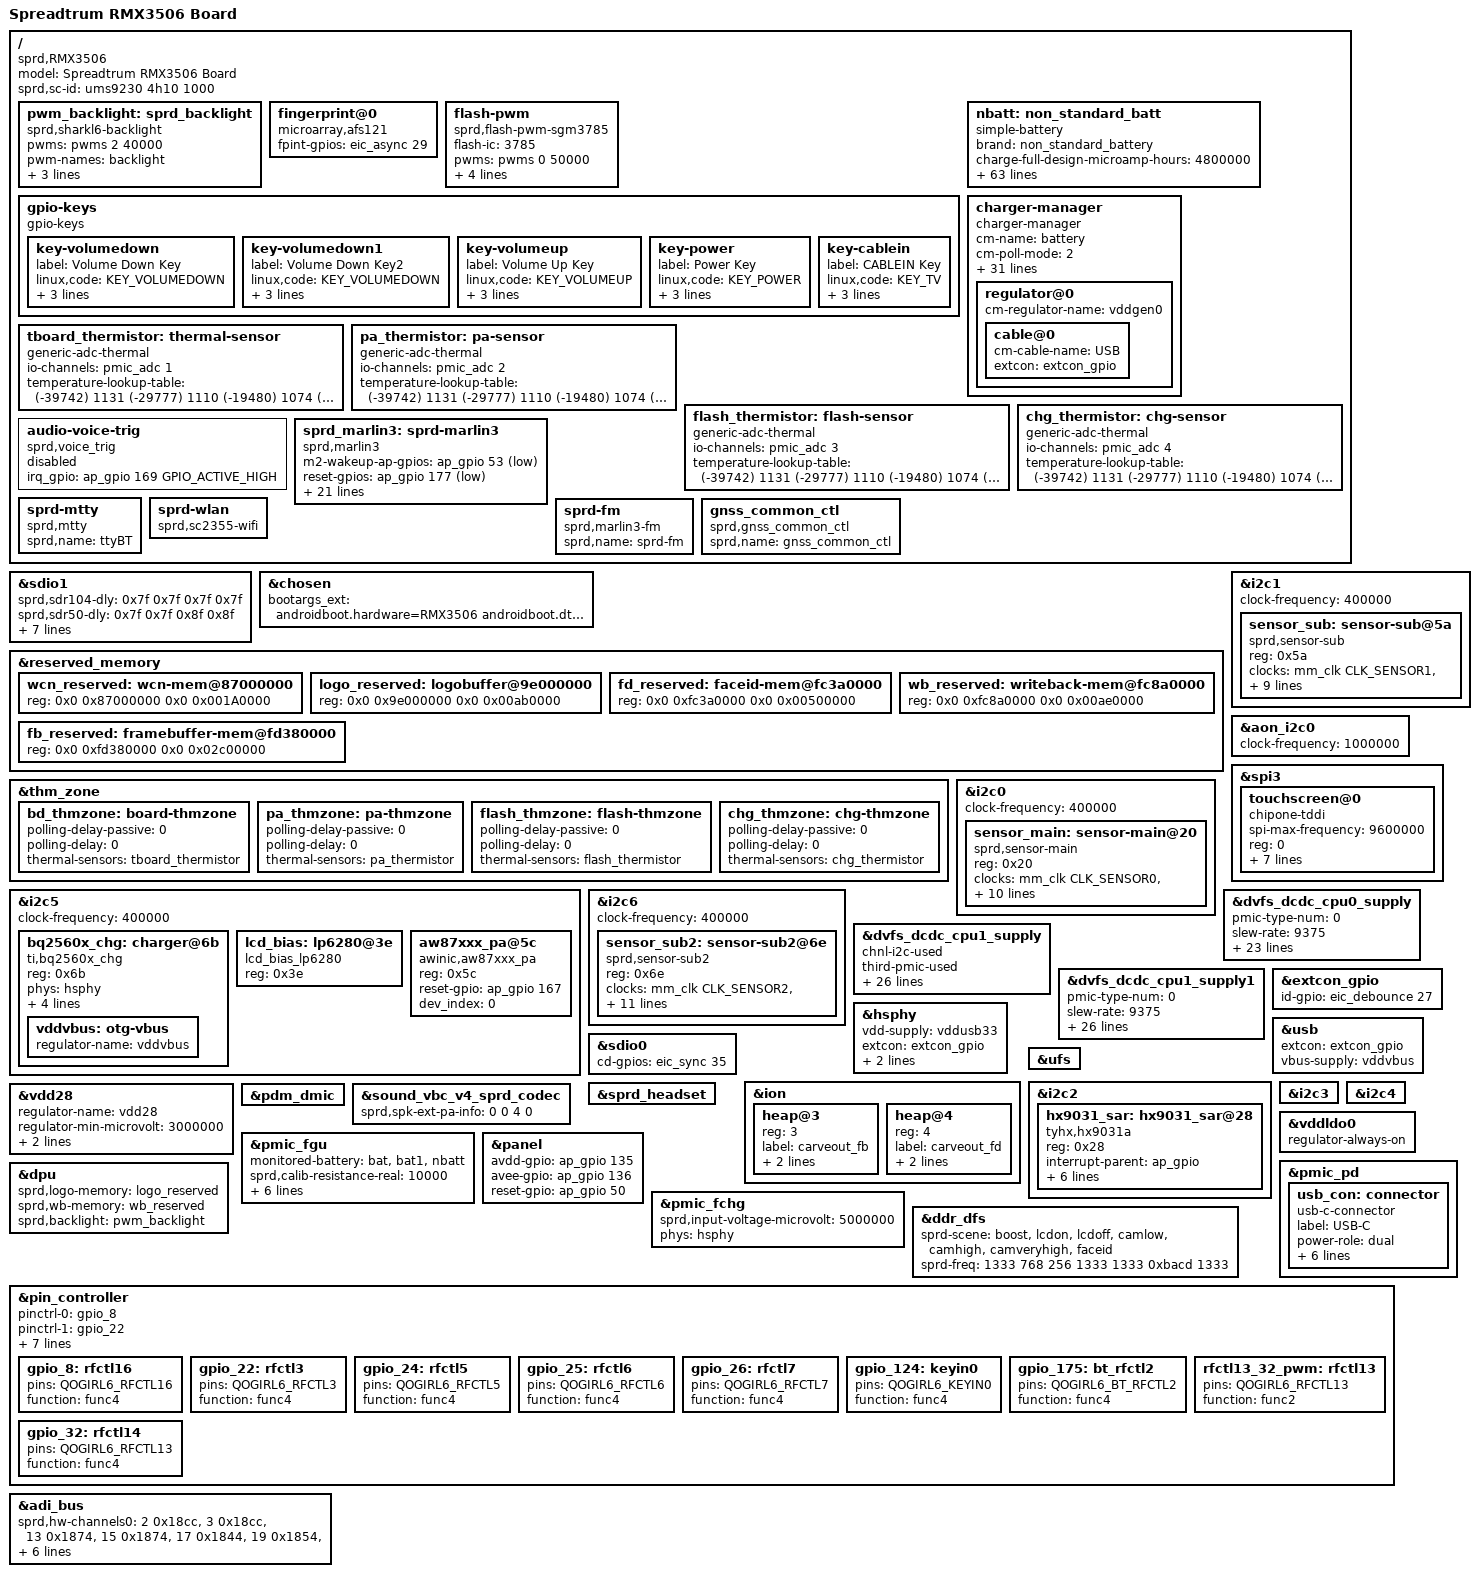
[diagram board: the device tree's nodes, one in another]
/dts-v1/;
/plugin/;
#include <dt-bindings/input/input.h>
#include <dt-bindings/gpio/gpio.h>
#include <dt-bindings/clock/sprd,ums9230-clk.h>
#include <dt-bindings/mfd/sprd,sc2730-regs.h>
#include <dt-bindings/mfd/sprd,sc2730-mask.h>
#include <dt-bindings/pinctrl/pinctrl-sprd.h>
#include <dt-bindings/usb/pd.h>
#include "lcd/lcd_icnl9911c_hkc_mipi_hd.dtsi"
#include "lcd/lcd_ili9882q_txd_mipi_hd.dtsi"
#include "lcd/lcd_icnl9911c_auo_mipi_hd.dtsi"
#include "lcd/lcd_dummy_mipi.dtsi"
#include "battery/RMX3506_REALME_LWN_4V45_5000mah.dtsi"
#include "battery/RMX3506_REALME_ATL_4V45_5000mah.dtsi"

/ {

	model = "Spreadtrum RMX3506 Board";

	compatible = "sprd,RMX3506";

	sprd,sc-id = "ums9230 4h10 1000";
	fragment {
		target-path = "/";
		__overlay__ {
			pwm_backlight: sprd_backlight {
				compatible = "sprd,sharkl6-backlight";
				pwms = <&pwms 2 40000>;
				pwm-names = "backlight";
				sprd,max-brightness-level = <3696>;
				default-brightness-level = <1048>;
				sprd,brightness-scale = <4095>;
			};

			fingerprint@0 {
				compatible = "microarray,afs121";
				fpint-gpios = <&eic_async 29 0>;
			};

			flash-pwm {
				compatible = "sprd,flash-pwm-sgm3785";
				flash-ic = <3785>;
				pwms = <&pwms 0 50000>;
				flash-en-gpios = <&ap_gpio 139 0>;
				flash-enm-gpios = <&ap_gpio 32 0>;
				pinctrl-names = "rfctl13_32_pwm","gpio_32";
				pinctrl-0 = <&rfctl13_32_pwm>;
				pinctrl-1 = <&gpio_32>;
				status = "okay";
			};

			gpio-keys {
				compatible = "gpio-keys";

				key-volumedown {
					label = "Volume Down Key";
					linux,code = <KEY_VOLUMEDOWN>;
					gpios = <&ap_gpio 124 GPIO_ACTIVE_LOW>;
					debounce-interval = <2>;
					wakeup-source;
				};
				
				key-volumedown1 {
					label = "Volume Down Key2";
					linux,code = <KEY_VOLUMEDOWN>;
					gpios = <&ap_gpio 126 GPIO_ACTIVE_LOW>;
					debounce-interval = <2>;
 					wakeup-source;
 				};

				key-volumeup {
					label = "Volume Up Key";
					linux,code = <KEY_VOLUMEUP>;
					gpios = <&pmic_eic 4 GPIO_ACTIVE_HIGH>;
					debounce-interval = <2>;
					wakeup-source;
				};

				key-power {
					label = "Power Key";
					linux,code = <KEY_POWER>;
					gpios = <&pmic_eic 1 GPIO_ACTIVE_LOW>;
					debounce-interval = <2>;
					wakeup-source;
				};
				key-cablein {
					label = "CABLEIN Key";
					linux,code = <KEY_TV>;
					gpios = <&ap_gpio 164 GPIO_ACTIVE_HIGH>;
					debounce-interval = <2>;
					wakeup-source;
				};
			};

			nbatt: non_standard_batt {
				compatible = "simple-battery";
				brand = "non_standard_battery";
				charge-full-design-microamp-hours = <4800000>;
				charge-term-current-microamp = <240000>;
				constant_charge_voltage_max_microvolt = <4432000>;
				factory-internal-resistance-micro-ohms = <130000>;
				voltage-min-design-microvolt = <3450000>;
				ocv-capacity-celsius = <20>;
				ocv-capacity-table-0 = <4380000 100>, <4317000 95>, <4258000 90>,
							<4200000 85>, <4145000 80>, <4092000 75>,
							<4047000 70>, <3990000 65>, <3955000 60>,
							<3900000 55>, <3861000 50>, <3834000 45>,
							<3813000 40>, <3796000 35>, <3783000 30>,
							<3770000 25>, <3752000 20>, <3730000 15>,
							<3698000 10>, <3687000 5>, <3400000 0>;
				 voltage-temp-table = <1404000 650>, <1307000 700>, <1203000 750>,
							<1095000 800>, <986000 850>, <878000 900>,
							<775000 950>, <678000 1000>, <590000 1050>,
							<510000 1100>, <440000 1150>, <378000 1200>,
							<324000 1250>, <278000 1300>, <238000 1350>,
							<204000 1400>, <175000 1450>, <150000 1500>,
							<129000 1550>, <111000 1600>, <96000 1650>,
							<83000 1700>, <73000 1750>, <63000 1800>,
							<55000 1850>, <48000 1900>, <42000 1950>;
				capacity-temp-table = <45 100>, <25 100>, <10 98>, <0 93>, <(-10) 85>, <(-20) 64>;
				resistance-temp-table = <45 100>, <25 100>, <10 546>, <0 769>, <(-10) 892>, <(-20) 923>;
				charge-sdp-current-microamp = <500000 600000>;
				charge-dcp-current-microamp = <2000000 3250000>;
				charge-cdp-current-microamp = <1500000 3250000>;
				charge-unknown-current-microamp = <1200000 1200000>;
		                cm-dcp-jeita-temp-table = <900 901 0 4435000 0 4435000>,
							<1000 1030 1000000 4435000 750000 4180000>,
							<1050 1080 2250000 4435000 1250000 4435000>,
							<1120 1150 2250000 4435000 2250000 4435000>,
							<1160 1190 3250000 4435000 2250000 4180000>,
							<1450 1420 3250000 4435000 3250000 4435000>,
							<1530 1500 1250000 4130000 1250000 4130000>;
				cm-sdp-jeita-temp-table = <900 901 0 4435000 0 4435000>,
							<1000 1030 600000 4435000 600000 4180000>,
							<1050 1080 600000 4435000 600000 4435000>,
							<1120 1150 600000 4435000 600000 4435000>,
							<1160 1190 600000 4435000 600000 4180000>,
							<1450 1420 600000 4435000 600000 4435000>,
							<1530 1500 600000 4130000 600000 4130000>;
				cm-cdp-jeita-temp-table = <900 901 0 4435000 0 4435000>,
							<1000 1030 1000000 4435000 750000 4180000>,
							<1050 1080 2250000 4435000 1250000 4180000>,
							<1120 1150 2250000 4435000 2250000 4435000>,
							<1160 1190 3250000 4435000 2250000 4180000>,
							<1450 1420 3250000 4435000 3250000 4435000>,
							<1530 1500 1250000 4130000 1250000 4130000>;
				cm-unknown-jeita-temp-table = <900 901 0 4435000 0 4180000>,
							<1000 1030 480000 4435000 480000 4180000>,
							<1050 1080 480000 4435000 480000 4435000>,
							<1120 1150 1000000 4435000 1000000 4435000>,
							<1160 1190 1200000 4435000 1200000 4435000>,
							<1450 1420 1200000 4435000 1200000 4435000>,
							<1530 1500 1000000 4130000 1000000 4130000>;
			};


			charger-manager {
				compatible = "charger-manager";
				cm-name = "battery";
				cm-poll-mode = <2>;
				cm-poll-interval = <5000>;
				cm-battery-stat = <2>;

				cm-fullbatt-vchkdrop-ms = <30000>;
				cm-fullbatt-vchkdrop-volt = <60000>;
				cm-fullbatt-voltage = <4395000 4395000>;
				cm-fullbatt-current = <260000>;
				cm-fullbatt-capacity = <100>;

				cm-num-chargers = <1>;
				cm-num-fast-chargers = <1>;
				cm-chargers = "bq2560x_charger";
				cm-fuel-gauge = "sc27xx-fgu";
				cm-fast-chargers = "sc2730_fast_charger";

				/* in deci centigrade */
				cm-battery-cold = <200>;
				cm-battery-cold-in-minus;
				cm-battery-hot = <800>;
				cm-battery-temp-diff = <100>;

				/* Allow charging for 6hr */
				cm-charging-max = <72000000>;
				/* recovery charging after stop charging 45min */
				cm-discharging-max = <2700000>;

				/* the interval to feed charger watchdog */
				cm-wdt-interval = <60>;

				/* drop voltage in microVolts to allow shutdown */
				cm-shutdown-voltage = <3350000>;

				/* when 99% of the time is exceeded, it will be forced to 100% */
				cm-tickle-time-out = <1500>;

				/* how much time to allow capacity change */
				cm-one-cap-time = <30>;
				cm-thermal-zone = "board-thmzone";
				/* when the safe charging voltage is exceeded, stop charging */
				cm-charge-voltage-max = <5800000>;
				/* drop voltage in microVolts to restart charging */
				cm-charge-voltage-drop = <350000>;

				cm-force-jeita-status = <5>;

				cm-ir-cv-offset-microvolt = <100000>;
				cm-ir-rc = <20>;
				cm-ir-us-upper-limit-microvolt = <4500000>;

				monitored-battery = <&bat &bat1 &nbatt>;
				cm-capacity-track;

				//cm-cap-remap-table = <1 2 3>, <2 3 2>, <98 99 2>, <99 100 3>;

				regulator@0 {
					cm-regulator-name = "vddgen0";
					cable@0 {
						cm-cable-name = "USB";
						extcon = <&extcon_gpio>;
					};
				};
			};

			tboard_thermistor: thermal-sensor {
				compatible = "generic-adc-thermal";
				#thermal-sensor-cells = <0>;
				io-channels = <&pmic_adc 1>;
				io-channel-names = "sensor-channel";
				temperature-lookup-table = <
					(-39742) 1131
					(-29777) 1110
					(-19480) 1074
					(-4679) 983
					10110 838
					24805 654
					44922 413
					54903 316
					64895 238
					74884 178
					84883 133
					94883 100
					104880 75
					114889 57
					124872 43 >;
			};

			pa_thermistor: pa-sensor {
				compatible = "generic-adc-thermal";
				#thermal-sensor-cells = <0>;
				io-channels = <&pmic_adc 2>;
				io-channel-names = "sensor-channel";
				temperature-lookup-table = <
					(-39742) 1131
					(-29777) 1110
					(-19480) 1074
					(-4679) 983
					10110 838
					24805 654
					44922 413
					54903 316
					64895 238
					74884 178
					84883 133
					94883 100
					104880 75
					114889 57
					124872 43 >;
			};
			
			flash_thermistor: flash-sensor {
				compatible = "generic-adc-thermal";
				#thermal-sensor-cells = <0>;
				io-channels = <&pmic_adc 3>;
				io-channel-names = "sensor-channel";
				temperature-lookup-table = <
					(-39742) 1131
					(-29777) 1110
					(-19480) 1074
					(-4679) 983
					10110 838
					24805 654
					44922 413
					54903 316
					64895 238
					74884 178
					84883 133
					94883 100
					104880 75
					114889 57
					124872 43 >;
			};

			chg_thermistor: chg-sensor {
				compatible = "generic-adc-thermal";
				#thermal-sensor-cells = <0>;
				io-channels = <&pmic_adc 4>;
				io-channel-names = "sensor-channel";
				temperature-lookup-table = <
					(-39742) 1131
					(-29777) 1110
					(-19480) 1074
					(-4679) 983
					10110 838
					24805 654
					44922 413
					54903 316
					64895 238
					74884 178
					84883 133
					94883 100
					104880 75
					114889 57
					124872 43 >;
			};

			audio-voice-trig {
				status = "disable";
				compatible = "sprd,voice_trig";
				irq_gpio = <&ap_gpio 169 GPIO_ACTIVE_HIGH>;
			};

			sprd_marlin3: sprd-marlin3 {
				compatible = "sprd,marlin3";
				m2-wakeup-ap-gpios = <&ap_gpio 53 GPIO_ACTIVE_LOW>;
				reset-gpios = <&ap_gpio 177 GPIO_ACTIVE_LOW>;
				enable-gpios = <&ap_gpio 116 GPIO_ACTIVE_LOW>;
				m2-to-ap-irq-gpios = <&ap_gpio 52 GPIO_ACTIVE_LOW>;
				avdd12-supply = <&vddwcn>;
				avdd33-supply = <&vddwifipa>;
				dcxo18-supply = <&vddsim2>;
                                xtal-26m-clk-type = "TSX";
				clock-names = "clk_32k","source","enable";
				clocks = <&aon_clk CLK_AUX2>,
					 <&ext_32k>,
					 <&aonapb_gate CLK_AUX2_EB>;

				reg = <0 0x87000000 0 0x00100000>,
					<0 0x87100000 0 0xA0000>;
				reg-names = "btwf_mem", "gnss_mem";

				sdhci-name = <&sdio1>;
				sprd,btwf-file-name = "/dev/block/by-name/wcnmodem";
				sprd,gnss-file-name = "/dev/block/by-name/gnssmodem";
				adma-tx;
				adma-rx;

				/*
				 * bound parameter:
				 * [0]:addr offset, [1]:mask, [2]:unboundval, [3]:boundval
				 */
				/*avdd12-parent-bound-chip = <REG_ANA_SLP_DCDC_PD_CTRL MASK_ANA_SLP_DCDCGEN1_PD_EN 0x0 MASK_ANA_SLP_DCDCGEN1_PD_EN>;*/
				avdd12-bound-wbreq = <REG_ANA_LDO_XTL_EN10 MASK_ANA_LDO_VDDWCN_EXT_XTL3_EN 0x0 MASK_ANA_LDO_VDDWCN_EXT_XTL3_EN>;
				avdd33-bound-wbreq = <REG_ANA_LDO_XTL_EN11 MASK_ANA_LDO_VDDWIFIPA_EXT_XTL3_EN 0x0 MASK_ANA_LDO_VDDWIFIPA_EXT_XTL3_EN>;
			};

			sprd-mtty {
				compatible = "sprd,mtty";
				sprd,name = "ttyBT";
			};

			sprd-fm {
				compatible = "sprd,marlin3-fm";
				sprd,name = "sprd-fm";
			};

			gnss_common_ctl {
				compatible = "sprd,gnss_common_ctl";
				sprd,name = "gnss_common_ctl";
			};

			sprd-wlan{
				compatible = "sprd,sc2355-wifi";
			};
		};
	};
};

&sdio1 {
	sprd,sdr104-dly = <0x7f 0x7f 0x7f 0x7f>;
	sprd,sdr50-dly = <0x7f 0x7f 0x8f 0x8f>;
	sd-uhs-sdr104;
	sd-uhs-sdr50;
	bus-width = <4>;
	sprd,name = "sdio_wifi";
	sprd,sdio-adma;
	no-sd;
	no-mmc;
	status = "okay";
};

&chosen {
	bootargs_ext = "androidboot.hardware=RMX3506 androidboot.dtbo_idx=0";
};

&reserved_memory {
	wcn_reserved: wcn-mem@87000000 {
		reg = <0x0 0x87000000 0x0 0x001A0000>;
	};

	logo_reserved: logobuffer@9e000000{
		reg = <0x0 0x9e000000 0x0 0x00ab0000>;
	};

	fd_reserved: faceid-mem@fc3a0000 {
		reg = <0x0 0xfc3a0000 0x0 0x00500000>;
	};

	wb_reserved: writeback-mem@fc8a0000 {
		reg = <0x0 0xfc8a0000 0x0 0x00ae0000>;
	};

	fb_reserved: framebuffer-mem@fd380000 {
		reg = <0x0 0xfd380000 0x0 0x02c00000>;
	};
};

&thm_zone {
	bd_thmzone: board-thmzone {
		polling-delay-passive = <0>;
		polling-delay = <0>;
		thermal-sensors = <&tboard_thermistor>;
	};

	pa_thmzone: pa-thmzone {
		polling-delay-passive = <0>;
		polling-delay = <0>;
		thermal-sensors = <&pa_thermistor>;
	};
	
	flash_thmzone: flash-thmzone {
		polling-delay-passive = <0>;
		polling-delay = <0>;
		thermal-sensors = <&flash_thermistor>;
	};

	chg_thmzone: chg-thmzone {
		polling-delay-passive = <0>;
		polling-delay = <0>;
		thermal-sensors = <&chg_thermistor>;
	};
};

&i2c0 {
	status = "okay";
	clock-frequency = <400000>;

	sensor_main: sensor-main@20 {
		compatible = "sprd,sensor-main";
		reg = <0x20>;
		clock-names = "clk_src","sensor_eb",
			"clk_96m","clk_76m8",
			"clk_48m","clk_26m";
		clocks = <&mm_clk CLK_SENSOR0>,<&mm_gate CLK_MM_SENSOR0_EB>,
				<&pll1 CLK_TWPLL_96M>,<&pll1 CLK_TWPLL_76M8>,
				<&pll1 CLK_TWPLL_48M>,<&ext_26m>;
		vddio-supply = <&vddcamio>;
		vddcama-supply = <&vddcama0>;
		vddcamd-supply = <&vddcamd0>;
		vddcammot-supply = <&vddcammot>;
		reset-gpios = <&ap_gpio 45 0>;
		sprd,phyid = <0>;
		csi = <&csi0>;
	};
};

&i2c1 {
	status = "okay";
	clock-frequency = <400000>;

	sensor_sub: sensor-sub@5a {
		compatible = "sprd,sensor-sub";
		reg = <0x5a>;
		clock-names = "clk_src","sensor_eb",
			"clk_96m","clk_76m8",
			"clk_48m","clk_26m";
		clocks = <&mm_clk CLK_SENSOR1>,<&mm_gate CLK_MM_SENSOR1_EB>,
				<&pll1 CLK_TWPLL_96M>,<&pll1 CLK_TWPLL_76M8>,
				<&pll1 CLK_TWPLL_48M>,<&ext_26m>;
		vddio-supply = <&vddcamio>;
		vddcama-supply = <&vddcama1>;
		vddcamd-supply = <&vddcamd0>;
		reset-gpios = <&ap_gpio 44 0>;
		sprd,phyid = <2>;
		csi = <&csi0>;
	};
};

&i2c5 {
	status = "okay";
	clock-frequency = <400000>;

	bq2560x_chg: charger@6b {
		compatible = "ti,bq2560x_chg";
		reg = <0x6b>;
		phys = <&hsphy>;
		monitored-battery = <&bat &bat1 &nbatt>;
		extcon = <&extcon_gpio>;
		pd-extcon-enable;
		irq-gpio = <&ap_gpio 115 GPIO_ACTIVE_LOW>;
		vddvbus:otg-vbus {
			regulator-name = "vddvbus";
		};
	};

	lcd_bias: lp6280@3e{
		compatible = "lcd_bias_lp6280";
		reg = <0x3e>;
	};

	aw87xxx_pa@5c {
		compatible = "awinic,aw87xxx_pa";
		reg = <0x5c>;
		reset-gpio = <&ap_gpio 167 0>;
		dev_index = < 0 >;
		status = "okay";
	};
};

&i2c6 {
	status = "okay";
	clock-frequency = <400000>;

	sensor_sub2: sensor-sub2@6e {
		compatible = "sprd,sensor-sub2";
		reg = <0x6e>;
		clock-names = "clk_src","sensor_eb",
			"clk_96m","clk_76m8",
			"clk_48m","clk_26m";
		clocks = <&mm_clk CLK_SENSOR2>,<&mm_gate CLK_MM_SENSOR2_EB>,
			<&pll1 CLK_TWPLL_96M>,<&pll1 CLK_TWPLL_76M8>,
			<&pll1 CLK_TWPLL_48M>,<&ext_26m>;
		vddio-supply = <&vddcamio>;
		avdd-gpios = <&ap_gpio 130 0>;
		vddcamd-supply = <&vddcamd1>;
		vddcammot-supply = <&vddcammot>;
		mot-gpios = <&ap_gpio 112 0>;
		reset-gpios = <&ap_gpio 114 0>;
	/*	power-down-gpios = <&ap_gpio 40 0>;*/
		sprd,phyid = <3>;
		csi = <&csi2>;
	};
};

&aon_i2c0 {
	status = "okay";
	clock-frequency = <1000000>;
};

&spi3 {
	status = "okay";
	touchscreen@0 {
			compatible = "chipone-tddi","tchip,ilitek";
			spi-max-frequency = <9600000>;
			reg = <0>;
			/*chipone,irq-gpio = <&ap_gpio 144 GPIO_ACTIVE_HIGH>;*/
			chipone,irq-gpio = <&eic_async 16  GPIO_ACTIVE_HIGH>;
			chipone,rst-gpio = <&ap_gpio 145 GPIO_ACTIVE_HIGH>;
			chipone,panel-coords = <0 720 0 1600>;
			chipone,x-res = <720>;
			chipone,y-res = <1600>;
		//ili
		/*touch,irq-gpio = <&ap_gpio 144 GPIO_ACTIVE_HIGH>;*/
		touch,irq-gpio = <&eic_async 16 GPIO_ACTIVE_HIGH>;
		touch,reset-gpio = <&ap_gpio 145 GPIO_ACTIVE_HIGH>;		
	};
};

&dvfs_dcdc_cpu0_supply {
	pmic-type-num = <0>;
	slew-rate = <9375>; /* 9375uV/us */
	top-dvfs-adi-state = <0x70 0 0xf>;
	voltage-grade-num = <8>;
	voltage-grade = <0 0xf0 0xf4 0 0x1ff>,
		<1 0xf0 0xf4 9 0x1ff>,
		<2 0x100 0xf4 18 0x1ff>,
		<3 0x110 0xf8 0 0x1ff>,
		<4 0x120 0xf8 9 0x1ff>,
		<5 0x130 0xf8 18 0x1ff>,
		<6 0x140 0xfc 0 0x1ff>,
		<7 0x140 0xfc 9 0x1ff>;
	voltage-up-delay = <50 0x58 0 0xffff 0x600>,
		<100 0x58 16 0xffff 0xa00>,
		<150 0x54 0 0xffff 0xf00>,
		<200 0x54 16 0xffff 0x1400>,
		<250 0x50 0 0xffff 0x1900>,
		<300 0x50 16 0xffff 0x1e00>,
		<350 0x110 0 0xffff 0x2300>;
	voltage-down-delay = <50 0x64 0 0xffff 0x600>,
		<100 0x64 16 0xffff 0xa00>,
		<150 0x60 0 0xffff 0xf00>,
		<200 0x60 16 0xffff 0x1400>,
		<250 0x5c 0 0xffff 0x1900>,
		<300 0x5c 16 0xffff 0x1e00>,
		<350 0x114 0 0xffff 0x2300>;
	tuning-latency-us = <0>;
	chnl-in-i2c = <0>;
};

&dvfs_dcdc_cpu1_supply {
	chnl-i2c-used;
	third-pmic-used;
	pmic-type-num = <2>;
	slew-rate = <4000>; /* 4000uV/us */
	supply-type-sel = <0x120 0 1>;
	top-dvfs-i2c-state = <0x9c 4 0x1f>;
	voltage-grade-num = <8>;
	voltage-grade = <0 0x8f 0x12c 0 0xff>,
		<1 0x94 0x12c 8 0xff>,
		<2 0x99 0x12c 16 0xff>,
		<3 0x9e 0x12c 24 0xff>,
		<4 0xa3 0x130 0 0xff>,
		<5 0xa8 0x130 8 0xff>,
		<6 0xa8 0x130 16 0xff>,
		<7 0xa8 0x130 24 0xff>;
	voltage-up-delay = <50 0x84 0 0xffff 0x1600>,
		<100 0x84 16 0xffff 0x1a00>,
		<150 0x80 0 0xffff 0x1f00>,
		<200 0x80 16 0xffff 0x2400>,
		<250 0x7c 0 0xffff 0x2900>,
		<300 0x7c 16 0xffff 0x2e00>,
		<350 0x118 0 0xffff 0x3300>;
	voltage-down-delay = <50 0x90 0 0xffff 0x600>,
		<100 0x90 16 0xffff 0xa00>,
		<150 0x8c 0 0xffff 0xf00>,
		<200 0x8c 16 0xffff 0x1400>,
		<250 0x88 0 0xffff 0x1900>,
		<300 0x88 16 0xffff 0x1e00>,
		<350 0x11c 0 0xffff 0x2300>;
	tuning-latency-us = <0>;
	chnl-in-i2c = <1>;
};

&dvfs_dcdc_cpu1_supply1 {
	pmic-type-num = <0>;
	slew-rate = <9375>; /* 9375uV/us */
	supply-type-sel = <0x120 0 0>;
	top-dvfs-adi-state = <0x9c 0 0xf>;
	voltage-grade-num = <8>;
	voltage-grade = <0 0xf0 0x100 0 0x1ff>,
		<1 0x100 0x100 9 0x1ff>,
		<2 0x110 0x100 18 0x1ff>,
		<3 0x120 0x104 0 0x1ff>,
		<4 0x130 0x104 9 0x1ff>,
		<5 0x140 0x104 18 0x1ff>,
		<6 0x140 0x108 0 0x1ff>,
		<7 0x140 0x108 9 0x1ff>;
	voltage-up-delay = <50 0x84 0 0xffff 0x600>,
		<100 0x84 16 0xffff 0xa00>,
		<150 0x80 0 0xffff 0xf00>,
		<200 0x80 16 0xffff 0x1400>,
		<250 0x7c 0 0xffff 0x1900>,
		<300 0x7c 16 0xffff 0x1e00>,
		<350 0x118 0 0xffff 0x2300>;
	voltage-down-delay = <50 0x90 0 0xffff 0x600>,
		<100 0x90 16 0xffff 0xa00>,
		<150 0x8c 0 0xffff 0xf00>,
		<200 0x8c 16 0xffff 0x1400>,
		<250 0x88 0 0xffff 0x1900>,
		<300 0x88 16 0xffff 0x1e00>,
		<350 0x11c 0 0xffff 0x2300>;
	tuning-latency-us = <0>;
	chnl-in-i2c = <0>;
};
&extcon_gpio {
	id-gpio = <&eic_debounce 27 GPIO_ACTIVE_HIGH>;
};
&hsphy {
	vdd-supply = <&vddusb33>;
	extcon = <&extcon_gpio>;
	sprd,hsphy-device-eye-pattern = <0x04f3d1c0>;
	sprd,hsphy-host-eye-pattern = <0x04f3d1c0>;
	status = "okay";
};

&usb {
	extcon = <&extcon_gpio>;
	vbus-supply = <&vddvbus>;
	status = "okay";
};

&sdio0 {
	cd-gpios = <&eic_sync 35 GPIO_ACTIVE_HIGH>;
};

&ion {
	heap@3 {
		reg = <3>;
		label = "carveout_fb";
		type = <2>;
		memory-region = <&fb_reserved>;
	};
};

&ufs {
	status = "okay";
};

&i2c2 {
	status = "okay";
    hx9031_sar:hx9031_sar@28 {
		compatible = "tyhx,hx9031a";
		reg = <0x28>;
		interrupt-parent = <&ap_gpio>;
		interrupts = <176 0>;
		tyhx,nirq-gpio = <&ap_gpio 176 0x00>;
		grip-sensor = <0>;
		grip-sensor-sub = <1>;
		grip-sensor-wifi = <2>;
		tyhx,channel-flag = <0x07>;
	};
};

&i2c3 {
	status = "okay";
};

&i2c4 {
	status = "okay";
};

&vdd28 {
    regulator-name = "vdd28";
    regulator-min-microvolt = <3000000>;
    regulator-max-microvolt = <3000000>;
    regulator-always-on;
};

&sprd_headset {
	status = "okay";
};

&pdm_dmic {
	status = "okay";
};

&sound_vbc_v4_sprd_codec {
	status = "okay";
    sprd,spk-ext-pa-info = <0 0 4 0>;
 /*   sprd,spk-ext-pa-gpio = <&ap_gpio 167 0>;*/
};

&vddldo0 {
	regulator-always-on;
};

&pmic_fgu {
	monitored-battery = <&bat &bat1 &nbatt>;
	sprd,calib-resistance-real = <10000>;
	sprd,calib-resistance-spec = <20000>;
	first-calib-voltage = <3580000>;
	first-calib-capacity = <50>;
	sprd,comp-resistance-mohm = <8>;
	io-channels = <&pmic_adc 0>, <&pmic_adc 14>, <&pmic_adc 6>;
 	io-channel-names = "bat-temp", "charge-vol", "bat-id-vol";
};

&panel {
	avdd-gpio = <&ap_gpio 135 GPIO_ACTIVE_HIGH>;
	avee-gpio = <&ap_gpio 136 GPIO_ACTIVE_HIGH>;
	reset-gpio = <&ap_gpio 50 GPIO_ACTIVE_HIGH>;
};

&dpu {
	sprd,logo-memory = <&logo_reserved>;
	sprd,wb-memory = <&wb_reserved>;

	sprd,backlight = <&pwm_backlight>;
};

&pmic_fchg {
	sprd,input-voltage-microvolt = <5000000>;
	phys = <&hsphy>;
};

&pmic_pd {
	status = "okay";
	usb_con: connector {
		compatible = "usb-c-connector";
		label = "USB-C";
		power-role = "dual";
		try-power-role = "sink";
		source-pdos = <PDO_FIXED(5000, 400, PDO_FIXED_USB_COMM)>;
		sink-pdos = <PDO_FIXED(5000, 3000, PDO_FIXED_USB_COMM)
			     PDO_PPS_APDO(3300, 11000, 3000)>;
		op-sink-microwatt = <10000000>;
	};
};

&ddr_dfs {
	  sprd-scene = "boost", "lcdon", "lcdoff", "camlow",
			"camhigh", "camveryhigh", "faceid";
	  sprd-freq = <1333 768 256 1333 1333 0xbacd 1333>;
};

&pin_controller {
	pinctrl-names =
	/* rfctl16 ,rfctl3, rfctl5 */
	"gpio_8", "gpio_22", "gpio_24",
	/* rfctl6, rfctl7, keyin0 */
	"gpio_25", "gpio_26", "gpio_124",
	/* bt_rfctl2 */
	"gpio_175", "rfctl13_32_pwm", "gpio_32";
	pinctrl-0 = <&gpio_8>;
	pinctrl-1 = <&gpio_22>;
	pinctrl-2 = <&gpio_24>;
	pinctrl-3 = <&gpio_25>;
	pinctrl-4 = <&gpio_26>;
	pinctrl-5 = <&gpio_124>;
	pinctrl-6 = <&gpio_175>;
	pinctrl-7 = <&rfctl13_32_pwm>;
	pinctrl-8 = <&gpio_32>;

	gpio_8: rfctl16 {
		pins = "QOGIRL6_RFCTL16";
		function = "func4";
	};

	gpio_22: rfctl3 {
		pins = "QOGIRL6_RFCTL3";
		function = "func4";
	};

	gpio_24: rfctl5 {
		pins = "QOGIRL6_RFCTL5";
		function = "func4";
	};

	gpio_25: rfctl6 {
		pins = "QOGIRL6_RFCTL6";
		function = "func4";
	};

	gpio_26: rfctl7 {
		pins = "QOGIRL6_RFCTL7";
		function = "func4";
	};

	gpio_124: keyin0 {
		pins = "QOGIRL6_KEYIN0";
		function = "func4";
	};

	gpio_175: bt_rfctl2 {
		pins = "QOGIRL6_BT_RFCTL2";
		function = "func4";
	};

	rfctl13_32_pwm: rfctl13 {
		pins = "QOGIRL6_RFCTL13";
		function = "func2";
	};

	gpio_32: rfctl14 {
		pins = "QOGIRL6_RFCTL13";
		function = "func4";
	};
};

&ion {
	heap@4 {
		reg = <4>;
		label = "carveout_fd";
		type = <2>;
		memory-region = <&fd_reserved>;
	};
};

&adi_bus {
	sprd,hw-channels0 = <2 0x18cc>, <3 0x18cc>, <13 0x1874>, <15 0x1874>,
			<17 0x1844>,<19 0x1854>, <21 0x1864>, <30 0x1820>,
			<35 0x19b8>, <39 0x19ac>, <32 0x197c>, <33 0x1988>;
	sprd,hw-channels1 = <2 0x18cc>, <3 0x18cc>, <13 0x1854>, <15 0x1874>,
			<17 0x1844>,<19 0x1844>, <21 0x1864>, <30 0x1820>,
			<35 0x19b8>, <39 0x19ac>, <32 0x197c>, <33 0x1988>;
};
